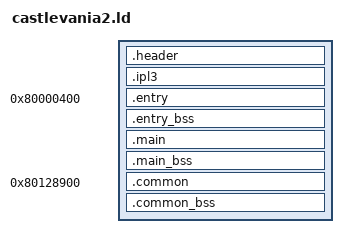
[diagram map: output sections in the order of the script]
SECTIONS
{
    __romPos = 0;
    header_ROM_START = __romPos;
    header_VRAM = ADDR(.header);
    .header : AT(header_ROM_START) SUBALIGN(16)
    {
        FILL(0x00000000);
        header_DATA_START = .;
        build/asm/header.o(.data);
        header_DATA_END = .;
        header_DATA_SIZE = ABSOLUTE(header_DATA_END - header_DATA_START);
    }
    __romPos += SIZEOF(.header);
    header_ROM_END = __romPos;
    header_VRAM_END = .;

    ipl3_ROM_START = __romPos;
    ipl3_VRAM = ADDR(.ipl3);
    .ipl3 : AT(ipl3_ROM_START) SUBALIGN(16)
    {
        FILL(0x00000000);
        ipl3_DATA_START = .;
        build/assets/ipl3.o(.data);
        ipl3_DATA_END = .;
        ipl3_DATA_SIZE = ABSOLUTE(ipl3_DATA_END - ipl3_DATA_START);
    }
    __romPos += SIZEOF(.ipl3);
    ipl3_ROM_END = __romPos;
    ipl3_VRAM_END = .;

    entry_ROM_START = __romPos;
    entry_VRAM = ADDR(.entry);
    .entry 0x80000400 : AT(entry_ROM_START) SUBALIGN(16)
    {
        FILL(0x00000000);
        entry_TEXT_START = .;
        build/asm/1000.o(.text);
        . = ALIGN(., 16);
        entry_TEXT_END = .;
        entry_TEXT_SIZE = ABSOLUTE(entry_TEXT_END - entry_TEXT_START);
        entry_DATA_START = .;
        build/asm/1000.o(.data);
        . = ALIGN(., 16);
        entry_DATA_END = .;
        entry_DATA_SIZE = ABSOLUTE(entry_DATA_END - entry_DATA_START);
        entry_RODATA_START = .;
        build/asm/1000.o(.rodata);
        . = ALIGN(., 16);
        entry_RODATA_END = .;
        entry_RODATA_SIZE = ABSOLUTE(entry_RODATA_END - entry_RODATA_START);
    }
    entry_bss_VRAM = ADDR(.entry_bss);
    .entry_bss (NOLOAD) : SUBALIGN(16)
    {
        FILL(0x00000000);
        entry_BSS_START = .;
        build/asm/1000.o(.bss);
        . = ALIGN(., 16);
        entry_BSS_END = .;
        entry_BSS_SIZE = ABSOLUTE(entry_BSS_END - entry_BSS_START);
    }
    __romPos += SIZEOF(.entry);
    __romPos = ALIGN(__romPos, 16);
    . = ALIGN(., 16);
    entry_ROM_END = __romPos;
    entry_VRAM_END = .;

    main_ROM_START = __romPos;
    main_VRAM = ADDR(.main);
    .main entry_VRAM_END : AT(main_ROM_START) SUBALIGN(16)
    {
        FILL(0x00000000);
        main_TEXT_START = .;
        build/asm/gamestate.o(.text);
        build/asm/memory.o(.text);
        build/asm/object.o(.text);
        build/asm/3550.o(.text);
        build/asm/4BC0.o(.text);
        build/asm/4D80.o(.text);
        build/asm/figure.o(.text);
        build/asm/D270.o(.text);
        build/asm/DD70.o(.text);
        build/asm/fade.o(.text);
        build/asm/object_flow.o(.text);
        build/asm/F960.o(.text);
        build/asm/10100.o(.text);
        build/asm/dma_manager.o(.text);
        build/asm/113D0.o(.text);
        build/asm/vec3f.o(.text);
        build/asm/12700.o(.text);
        build/asm/12900.o(.text);
        build/asm/main.o(.text);
        build/asm/15C80.o(.text);
        build/asm/16510.o(.text);
        build/asm/16640.o(.text);
        build/asm/scheduler.o(.text);
        build/asm/17040.o(.text);
        build/asm/172F0.o(.text);
        build/asm/controller.o(.text);
        build/asm/17A00.o(.text);
        build/asm/dma.o(.text);
        build/asm/18430.o(.text);
        build/asm/18E40.o(.text);
        build/asm/18FC0.o(.text);
        build/asm/19340.o(.text);
        build/asm/19570.o(.text);
        build/asm/19620.o(.text);
        build/asm/19630.o(.text);
        build/asm/19E20.o(.text);
        build/asm/19F40.o(.text);
        build/asm/crash_screen_init.o(.text);
        build/asm/debug.o(.text);
        build/asm/1AE50.o(.text);
        build/asm/controller_pak.o(.text);
        build/asm/save.o(.text);
        build/asm/1C830.o(.text);
        build/asm/22350.o(.text);
        build/asm/25F80.o(.text);
        build/asm/2BC60.o(.text);
        build/asm/2D5D0.o(.text);
        build/asm/2FA90.o(.text);
        build/asm/333F0.o(.text);
        build/asm/39330.o(.text);
        build/asm/enemy_list.o(.text);
        build/asm/3F870.o(.text);
        build/asm/407B0.o(.text);
        build/asm/atari.o(.text);
        build/asm/451C0.o(.text);
        build/asm/458C0.o(.text);
        build/asm/45C80.o(.text);
        build/asm/46140.o(.text);
        build/asm/46520.o(.text);
        build/asm/47AA0.o(.text);
        build/asm/47FD0.o(.text);
        build/asm/483A0.o(.text);
        build/asm/48780.o(.text);
        build/asm/48B40.o(.text);
        build/asm/49100.o(.text);
        build/asm/49D80.o(.text);
        build/asm/4A310.o(.text);
        build/asm/4ADB0.o(.text);
        build/asm/4B630.o(.text);
        build/asm/4C0A0.o(.text);
        build/asm/4C7A0.o(.text);
        build/asm/4CDE0.o(.text);
        build/asm/4D470.o(.text);
        build/asm/effect/fire.o(.text);
        build/asm/4DEC0.o(.text);
        build/asm/4F3C0.o(.text);
        build/asm/4F5E0.o(.text);
        build/asm/51CB0.o(.text);
        build/asm/52710.o(.text);
        build/asm/52910.o(.text);
        build/asm/52D50.o(.text);
        build/asm/54E70.o(.text);
        build/asm/55050.o(.text);
        build/asm/552F0.o(.text);
        build/asm/554D0.o(.text);
        build/asm/556B0.o(.text);
        build/asm/55890.o(.text);
        build/asm/55C90.o(.text);
        build/asm/55E70.o(.text);
        build/asm/effect/fire_sparkles.o(.text);
        build/asm/566D0.o(.text);
        build/asm/56B60.o(.text);
        build/asm/57050.o(.text);
        build/asm/574C0.o(.text);
        build/asm/5B620.o(.text);
        build/asm/5B7E0.o(.text);
        build/asm/effect_manager.o(.text);
        build/asm/effect.o(.text);
        build/asm/610F0.o(.text);
        build/asm/63A60.o(.text);
        build/asm/6A4A0.o(.text);
        build/asm/6A990.o(.text);
        build/asm/6AE70.o(.text);
        build/asm/6C0B0.o(.text);
        build/asm/6CB40.o(.text);
        build/asm/70460.o(.text);
        build/asm/70C90.o(.text);
        build/asm/71180.o(.text);
        build/asm/72060.o(.text);
        build/asm/72700.o(.text);
        build/asm/72D90.o(.text);
        build/asm/72DA0.o(.text);
        build/asm/72DB0.o(.text);
        build/asm/73D80.o(.text);
        build/asm/750B0.o(.text);
        build/asm/75730.o(.text);
        build/asm/76AE0.o(.text);
        build/asm/audio/audioMgr.o(.text);
        build/asm/audio/audio.o(.text);
        build/asm/7CBB0.o(.text);
        build/asm/7E080.o(.text);
        build/asm/libultra/os/sendmesg.o(.text);
        build/asm/libultra/io/pfsfreeblocks.o(.text);
        build/asm/libultra/gu/perspective.o(.text);
        build/asm/libultra/os/recvmesg.o(.text);
        build/asm/libultra/os/setintmask.o(.text);
        build/asm/libultra/al/sl.o(.text);
        build/asm/libultra/gu/align.o(.text);
        build/asm/libultra/gu/sinf.o(.text);
        build/asm/libultra/gu/sins.o(.text);
        build/asm/libultra/al/synsetvol.o(.text);
        build/asm/libultra/io/sptask.o(.text);
        build/asm/libultra/os/os_tlb.o(.text);
        build/asm/libultra/os/exceptasm.o(.text);
        build/asm/libultra/os/thread.o(.text);
        build/asm/libultra/os/destroythread.o(.text);
        build/asm/libultra/io/piread.o(.text);
        build/asm/libultra/io/piacs.o(.text);
        build/asm/libultra/io/controller.o(.text);
        build/asm/libultra/io/siacs.o(.text);
        build/asm/libultra/os/createthread.o(.text);
        build/asm/libultra/io/contreaddata.o(.text);
        build/asm/libultra/gu/rotate.o(.text);
        build/asm/libultra/al/synallocvoice.o(.text);
        build/asm/libultra/os/virtualtophysical.o(.text);
        build/asm/libultra/os/writebackdcache.o(.text);
        build/asm/libultra/os/initialize.o(.text);
        build/asm/libultra/libc/ll.o(.text);
        build/asm/libultra/libc/bzero.o(.text);
        build/asm/libultra/os/setsr.o(.text);
        build/asm/libultra/os/getsr.o(.text);
        build/asm/libultra/audio/synsetfxparam.o(.text);
        build/asm/libultra/io/vigetnextframebuf.o(.text);
        build/asm/libultra/audio/synstartvoice.o(.text);
        build/asm/libultra/io/sprawdma.o(.text);
        build/asm/libultra/io/sirawdma.o(.text);
        build/asm/libultra/io/viblack.o(.text);
        build/asm/libultra/io/pirawread.o(.text);
        build/asm/libultra/io/sirawread.o(.text);
        build/asm/libultra/io/sptaskyield.o(.text);
        build/asm/libultra/io/pfsreadwritefile.o(.text);
        build/asm/libultra/io/pfsgetstatus.o(.text);
        build/asm/libultra/gu/mtxutil.o(.text);
        build/asm/libultra/io/visetmode.o(.text);
        build/asm/libultra/io/motor.o(.text);
        build/asm/libultra/io/pfsallocatefile.o(.text);
        build/asm/libultra/io/pfsisplug.o(.text);
        build/asm/libultra/audio/synsetpitch.o(.text);
        build/asm/libultra/os/probetlb.o(.text);
        build/asm/libultra/io/pimgr.o(.text);
        build/asm/libultra/io/devmgr.o(.text);
        build/asm/libultra/io/pirawdma.o(.text);
        build/asm/libultra/audio/synsetpan.o(.text);
        build/asm/libultra/os/getcount.o(.text);
        build/asm/libultra/io/contpfs.o(.text);
        build/asm/libultra/io/pidma.o(.text);
        build/asm/libultra/io/pfssearchfile.o(.text);
        build/asm/libultra/audio/synthesizer.o(.text);
        build/asm/libultra/audio/drvrnew.o(.text);
        build/asm/libultra/audio/mainbus.o(.text);
        build/asm/libultra/audio/reverb.o(.text);
        build/asm/libultra/audio/auxbus.o(.text);
        build/asm/libultra/audio/env.o(.text);
        build/asm/libultra/audio/resample.o(.text);
        build/asm/libultra/audio/load.o(.text);
        build/asm/libultra/os/seteventmesg.o(.text);
        build/asm/libultra/gu/sqrtf.o(.text);
        build/asm/libultra/os/afterprenmi.o(.text);
        build/asm/libultra/io/contquery.o(.text);
        build/asm/libultra/gu/random.o(.text);
        build/asm/libultra/os/unmaptlb.o(.text);
        build/asm/libultra/libc/xprintf.o(.text);
        build/asm/libultra/audio/filter.o(.text);
        build/asm/libultra/gu/ortho.o(.text);
        build/asm/libultra/os/unmaptlball.o(.text);
        build/asm/libultra/io/epidma.o(.text);
        build/asm/libultra/audio/heapinit.o(.text);
        build/asm/libultra/libc/string.o(.text);
        build/asm/libultra/os/invalicache.o(.text);
        build/asm/libultra/os/createmesgqueue.o(.text);
        build/asm/libultra/os/invaldcache.o(.text);
        build/asm/libultra/audio/synsetfxmix.o(.text);
        build/asm/libultra/audio/save.o(.text);
        build/asm/libultra/io/pfsrepairid.o(.text);
        build/asm/libultra/audio/syngetfxref.o(.text);
        build/asm/libultra/io/sp.o(.text);
        build/asm/libultra/io/si.o(.text);
        build/asm/libultra/gu/translate.o(.text);
        build/asm/libultra/os/jammesg.o(.text);
        build/asm/libultra/os/setthreadpri.o(.text);
        build/asm/libultra/os/getthreadpri.o(.text);
        build/asm/libultra/io/epirawread.o(.text);
        build/asm/libultra/io/viswapbuf.o(.text);
        build/asm/libultra/gu/lookat.o(.text);
        build/asm/libultra/gu/position.o(.text);
        build/asm/libultra/io/epirawdma.o(.text);
        build/asm/libultra/io/sptaskyielded.o(.text);
        build/asm/libultra/libc/bcmp.o(.text);
        build/asm/libultra/os/gettime.o(.text);
        build/asm/libultra/os/timerintr.o(.text);
        build/asm/libultra/os/setglobalintmask.o(.text);
        build/asm/libultra/io/aisetfreq.o(.text);
        build/asm/libultra/gu/normalize.o(.text);
        build/asm/libultra/os/setcompare.o(.text);
        build/asm/libultra/libc/bcopy.o(.text);
        build/asm/libultra/audio/copy.o(.text);
        build/asm/libultra/os/resetglobalintmask.o(.text);
        build/asm/libultra/io/pfsdeletefile.o(.text);
        build/asm/libultra/os/interrupt.o(.text);
        build/asm/libultra/io/vi.o(.text);
        build/asm/libultra/io/viswapcontext.o(.text);
        build/asm/libultra/io/pigetcmdq.o(.text);
        build/asm/libultra/gu/cosf.o(.text);
        build/asm/libultra/gu/coss.o(.text);
        build/asm/libultra/io/visetspecial.o(.text);
        build/asm/libultra/io/visetevent.o(.text);
        build/asm/libultra/audio/synaddplayer.o(.text);
        build/asm/libultra/io/pfsnumfiles.o(.text);
        build/asm/libultra/io/cartrominit.o(.text);
        build/asm/libultra/io/pfsselectbank.o(.text);
        build/asm/libultra/os/setfpccsr.o(.text);
        build/asm/libultra/io/pfsfilestate.o(.text);
        build/asm/libultra/io/pfsinitpak.o(.text);
        build/asm/libultra/io/pfschecker.o(.text);
        build/asm/libultra/io/aigetlen.o(.text);
        build/asm/libultra/io/piwrite.o(.text);
        build/asm/libultra/os/maptlbrdb.o(.text);
        build/asm/libultra/os/yieldthread.o(.text);
        build/asm/libultra/audio/synstartvoiceparam.o(.text);
        build/asm/libultra/os/getcause.o(.text);
        build/asm/libultra/io/contramwrite.o(.text);
        build/asm/libultra/io/contramread.o(.text);
        build/asm/libultra/io/crc.o(.text);
        build/asm/libultra/io/epirawwrite.o(.text);
        build/asm/libultra/os/settimer.o(.text);
        build/asm/libultra/libc/xldtob.o(.text);
        build/asm/libultra/libc/ldiv.o(.text);
        build/asm/libultra/libc/xlitob.o(.text);
        build/asm/libultra/io/sirawwrite.o(.text);
        build/asm/libultra/io/pirawwrite.o(.text);
        build/asm/libultra/io/spsetstat.o(.text);
        build/asm/libultra/io/spgetstat.o(.text);
        build/asm/libultra/io/vimgr.o(.text);
        build/asm/libultra/io/vigetcurrcontext.o(.text);
        build/asm/libultra/os/writebackdcacheall.o(.text);
        build/asm/libultra/audio/heapalloc.o(.text);
        build/asm/libultra/os/getcurrfaultthread.o(.text);
        build/asm/libultra/gu/rotaterpy.o(.text);
        build/asm/libultra/libc/llcvt.o(.text);
        build/asm/libultra/os/startthread.o(.text);
        build/asm/libultra/io/visetyscale.o(.text);
        build/asm/libultra/audio/synallocfx.o(.text);
        build/asm/libultra/audio/synstopvoice.o(.text);
        build/asm/libultra/audio/syndelete.o(.text);
        build/asm/libultra/io/aisetnextbuf.o(.text);
        build/asm/libultra/io/ai.o(.text);
        build/asm/libultra/io/vigetcurrframebuf.o(.text);
        build/asm/libultra/io/spsetpc.o(.text);
        . = ALIGN(., 16);
        main_TEXT_END = .;
        main_TEXT_SIZE = ABSOLUTE(main_TEXT_END - main_TEXT_START);
        main_DATA_START = .;
        build/asm/data/908D0.data.o(.data);
        build/asm/data/90920.data.o(.data);
        build/asm/data/gamestate.data.o(.data);
        build/asm/memory.o(.data);
        build/asm/data/object.data.o(.data);
        build/asm/3550.o(.data);
        build/asm/4BC0.o(.data);
        build/asm/data/4D80.data.o(.data);
        build/asm/data/93B50.data.o(.data);
        build/asm/data/figure.data.o(.data);
        build/asm/data/D270.data.o(.data);
        build/asm/data/fade.data.o(.data);
        build/asm/data/F960.data.o(.data);
        build/asm/data/10100.data.o(.data);
        build/asm/dma_manager.o(.data);
        build/asm/data/DMAMgr.data.o(.data);
        build/asm/data/113D0.data.o(.data);
        build/asm/vec3f.o(.data);
        build/asm/12700.o(.data);
        build/asm/data/94940.data.o(.data);
        build/asm/data/19630.data.o(.data);
        build/asm/19E20.o(.data);
        build/asm/19F40.o(.data);
        build/asm/data/crash_screen_init.data.o(.data);
        build/asm/data/func_80096760.data.o(.data);
        build/asm/data/func_800968B0.data.o(.data);
        build/asm/data/func_80096A50.data.o(.data);
        build/asm/data/debug.data.o(.data);
        build/asm/data/save.data.o(.data);
        build/asm/data/97710.data.o(.data);
        build/asm/data/enemy_list.data.o(.data);
        build/asm/3F870.o(.data);
        build/asm/407B0.o(.data);
        build/asm/data/atari.data.o(.data);
        build/asm/451C0.o(.data);
        build/asm/458C0.o(.data);
        build/asm/45C80.o(.data);
        build/asm/46140.o(.data);
        build/asm/46520.o(.data);
        build/asm/47AA0.o(.data);
        build/asm/47FD0.o(.data);
        build/asm/483A0.o(.data);
        build/asm/48780.o(.data);
        build/asm/48B40.o(.data);
        build/asm/49100.o(.data);
        build/asm/49D80.o(.data);
        build/asm/4A310.o(.data);
        build/asm/4ADB0.o(.data);
        build/asm/4B630.o(.data);
        build/asm/4C0A0.o(.data);
        build/asm/4C7A0.o(.data);
        build/asm/4CDE0.o(.data);
        build/asm/4D470.o(.data);
        build/asm/data/effect/fire.data.o(.data);
        build/asm/4DEC0.o(.data);
        build/asm/4F3C0.o(.data);
        build/asm/4F5E0.o(.data);
        build/asm/51CB0.o(.data);
        build/asm/52710.o(.data);
        build/asm/52910.o(.data);
        build/asm/52D50.o(.data);
        build/asm/54E70.o(.data);
        build/asm/55050.o(.data);
        build/asm/552F0.o(.data);
        build/asm/554D0.o(.data);
        build/asm/556B0.o(.data);
        build/asm/55890.o(.data);
        build/asm/55C90.o(.data);
        build/asm/55E70.o(.data);
        build/asm/data/9B680.data.o(.data);
        build/asm/data/effect/fire_sparkles.data.o(.data);
        build/asm/566D0.o(.data);
        build/asm/data/9B8B0.data.o(.data);
        build/asm/data/56B60.data.o(.data);
        build/asm/data/57050.data.o(.data);
        build/asm/data/574C0.data.o(.data);
        build/asm/data/5B620.data.o(.data);
        build/asm/data/5B7E0.data.o(.data);
        build/asm/data/effect_manager.data.o(.data);
        build/asm/effect.o(.data);
        build/asm/610F0.o(.data);
        build/asm/63A60.o(.data);
        build/asm/6A4A0.o(.data);
        build/asm/6A990.o(.data);
        build/asm/6AE70.o(.data);
        build/asm/6C0B0.o(.data);
        build/asm/6CB40.o(.data);
        build/asm/70460.o(.data);
        build/asm/70C90.o(.data);
        build/asm/71180.o(.data);
        build/asm/72060.o(.data);
        build/asm/72700.o(.data);
        build/asm/72D90.o(.data);
        build/asm/72DA0.o(.data);
        build/asm/72DB0.o(.data);
        build/asm/73D80.o(.data);
        build/asm/750B0.o(.data);
        build/asm/75730.o(.data);
        build/asm/76AE0.o(.data);
        build/asm/data/9B970.data.o(.data);
        build/asm/data/libultra/os/initialize.data.o(.data);
        build/asm/libultra/libc/ll.o(.data);
        build/asm/libultra/libc/bzero.o(.data);
        build/asm/libultra/os/setsr.o(.data);
        build/asm/libultra/os/getsr.o(.data);
        build/asm/libultra/audio/synsetfxparam.o(.data);
        build/asm/libultra/io/vigetnextframebuf.o(.data);
        build/asm/libultra/audio/synstartvoice.o(.data);
        build/asm/libultra/io/sprawdma.o(.data);
        build/asm/libultra/io/sirawdma.o(.data);
        build/asm/libultra/io/viblack.o(.data);
        build/asm/libultra/io/pirawread.o(.data);
        build/asm/libultra/io/sirawread.o(.data);
        build/asm/libultra/io/sptaskyield.o(.data);
        build/asm/libultra/io/pfsreadwritefile.o(.data);
        build/asm/libultra/io/pfsgetstatus.o(.data);
        build/asm/libultra/gu/mtxutil.o(.data);
        build/asm/libultra/io/visetmode.o(.data);
        build/asm/libultra/io/motor.o(.data);
        build/asm/libultra/io/pfsallocatefile.o(.data);
        build/asm/libultra/io/pfsisplug.o(.data);
        build/asm/libultra/audio/synsetpitch.o(.data);
        build/asm/libultra/os/probetlb.o(.data);
        build/asm/data/libultra/io/pimgr.data.o(.data);
        build/asm/data/libultra/io/contpfs.data.o(.data);
        build/asm/libultra/io/pidma.o(.data);
        build/asm/libultra/io/pfssearchfile.o(.data);
        build/asm/data/libultra/audio/drvrnew.data.o(.data);
        build/asm/data/libultra/audio/env.data.o(.data);
        build/asm/data/func_800A23B0.data.o(.data);
        build/asm/data/libultra/os/seteventmesg.data.o(.data);
        build/asm/libultra/gu/sqrtf.o(.data);
        build/asm/libultra/os/afterprenmi.o(.data);
        build/asm/libultra/io/contquery.o(.data);
        build/asm/data/libultra/gu/random.data.o(.data);
        build/asm/libultra/os/unmaptlb.o(.data);
        build/asm/data/libultra/libc/xprintf.data.o(.data);
        build/asm/data/libultra/os/timerintr.data.o(.data);
        build/asm/libultra/os/setglobalintmask.o(.data);
        build/asm/libultra/io/aisetfreq.o(.data);
        build/asm/libultra/gu/normalize.o(.data);
        build/asm/libultra/os/setcompare.o(.data);
        build/asm/libultra/libc/bcopy.o(.data);
        build/asm/libultra/audio/copy.o(.data);
        build/asm/libultra/os/resetglobalintmask.o(.data);
        build/asm/libultra/io/pfsdeletefile.o(.data);
        build/asm/libultra/os/interrupt.o(.data);
        build/asm/data/libultra/io/vi.data.o(.data);
        build/asm/libultra/io/viswapcontext.o(.data);
        build/asm/libultra/io/pigetcmdq.o(.data);
        build/asm/data/A31B0.data.o(.data);
        build/asm/data/libultra/io/cartrominit.data.o(.data);
        build/asm/libultra/io/pfsselectbank.o(.data);
        build/asm/libultra/os/setfpccsr.o(.data);
        build/asm/libultra/io/pfsfilestate.o(.data);
        build/asm/libultra/io/pfsinitpak.o(.data);
        build/asm/libultra/io/pfschecker.o(.data);
        build/asm/libultra/io/aigetlen.o(.data);
        build/asm/libultra/io/piwrite.o(.data);
        build/asm/libultra/os/maptlbrdb.o(.data);
        build/asm/libultra/os/yieldthread.o(.data);
        build/asm/libultra/audio/synstartvoiceparam.o(.data);
        build/asm/libultra/os/getcause.o(.data);
        build/asm/libultra/io/contramwrite.o(.data);
        build/asm/data/libultra/io/contramread.data.o(.data);
        build/asm/libultra/io/crc.o(.data);
        build/asm/libultra/io/epirawwrite.o(.data);
        build/asm/libultra/os/settimer.o(.data);
        build/asm/data/libultra/libc/xlitob.data.o(.data);
        build/asm/libultra/io/sirawwrite.o(.data);
        build/asm/libultra/io/pirawwrite.o(.data);
        build/asm/libultra/io/spsetstat.o(.data);
        build/asm/libultra/io/spgetstat.o(.data);
        build/asm/data/libultra/io/vimgr.data.o(.data);
        build/asm/libultra/io/vigetcurrcontext.o(.data);
        build/asm/libultra/os/writebackdcacheall.o(.data);
        build/asm/libultra/audio/heapalloc.o(.data);
        build/asm/libultra/os/getcurrfaultthread.o(.data);
        build/asm/data/libultra/io/aisetnextbuf.data.o(.data);
        build/asm/libultra/io/ai.o(.data);
        build/asm/libultra/io/vigetcurrframebuf.o(.data);
        build/asm/libultra/io/spsetpc.o(.data);
        build/asm/data/4D80.data.o(.data);
        build/asm/data/figure.data.o(.data);
        build/asm/data/D270.data.o(.data);
        build/asm/data/DD70.data.o(.data);
        build/asm/data/fade.data.o(.data);
        build/asm/object_flow.o(.data);
        build/asm/data/A33C0.data.o(.data);
        build/asm/data/A3410.data.o(.data);
        build/asm/data/12900.data.o(.data);
        build/asm/main.o(.data);
        build/asm/15C80.o(.data);
        build/asm/16510.o(.data);
        build/asm/16640.o(.data);
        build/asm/scheduler.o(.data);
        build/asm/data/17A00.data.o(.data);
        build/asm/dma.o(.data);
        build/asm/18430.o(.data);
        build/asm/18E40.o(.data);
        build/asm/18FC0.o(.data);
        build/asm/19340.o(.data);
        build/asm/19570.o(.data);
        build/asm/19620.o(.data);
        build/asm/data/crash_screen_init.data.o(.data);
        build/asm/data/debug.data.o(.data);
        build/asm/1AE50.o(.data);
        build/asm/controller_pak.o(.data);
        build/asm/data/save.data.o(.data);
        build/asm/1C830.o(.data);
        build/asm/22350.o(.data);
        build/asm/25F80.o(.data);
        build/asm/2BC60.o(.data);
        build/asm/2D5D0.o(.data);
        build/asm/2FA90.o(.data);
        build/asm/333F0.o(.data);
        build/asm/39330.o(.data);
        build/asm/data/A3D10.data.o(.data);
        build/asm/data/A41E0.data.o(.data);
        build/asm/data/A4310.data.o(.data);
        build/asm/data/A45A0.data.o(.data);
        build/asm/data/A4650.data.o(.data);
        build/asm/data/A4670.data.o(.data);
        build/asm/data/A49E0.data.o(.data);
        build/asm/data/A6A20.data.o(.data);
        build/asm/data/A6C40.data.o(.data);
        build/asm/data/A6CD0.data.o(.data);
        build/asm/data/A6E70.data.o(.data);
        build/asm/data/A6E90.data.o(.data);
        build/asm/data/A6EB0.data.o(.data);
        build/asm/data/A7000.data.o(.data);
        build/asm/data/A70E0.data.o(.data);
        build/asm/data/A7100.data.o(.data);
        build/asm/data/A7280.data.o(.data);
        build/asm/data/A72B0.data.o(.data);
        build/asm/data/A7360.data.o(.data);
        build/asm/data/A73A0.data.o(.data);
        build/asm/data/A73D0.data.o(.data);
        build/asm/data/A7400.data.o(.data);
        build/asm/data/A7420.data.o(.data);
        build/asm/data/A7480.data.o(.data);
        build/asm/data/A74C0.data.o(.data);
        build/asm/data/A7500.data.o(.data);
        build/asm/data/A75F0.data.o(.data);
        build/asm/data/A7790.data.o(.data);
        build/asm/data/A78C0.data.o(.data);
        build/asm/data/libultra/gu/perspective.data.o(.data);
        build/asm/libultra/os/recvmesg.o(.data);
        build/asm/libultra/os/setintmask.o(.data);
        build/asm/libultra/al/sl.o(.data);
        build/asm/data/A78F0.data.o(.data);
        build/asm/data/libultra/gu/align.data.o(.data);
        build/asm/data/libultra/gu/sinf.data.o(.data);
        build/asm/libultra/gu/sins.o(.data);
        build/asm/libultra/al/synsetvol.o(.data);
        build/asm/libultra/io/sptask.o(.data);
        build/asm/libultra/os/os_tlb.o(.data);
        build/asm/data/libultra/os/exceptasm.data.o(.data);
        build/asm/libultra/os/thread.o(.data);
        build/asm/libultra/os/destroythread.o(.data);
        build/asm/libultra/io/piread.o(.data);
        build/asm/libultra/io/piacs.o(.data);
        build/asm/libultra/io/controller.o(.data);
        build/asm/libultra/io/siacs.o(.data);
        build/asm/libultra/os/createthread.o(.data);
        build/asm/libultra/io/contreaddata.o(.data);
        build/asm/data/libultra/gu/rotate.data.o(.data);
        build/asm/libultra/al/synallocvoice.o(.data);
        build/asm/libultra/os/virtualtophysical.o(.data);
        build/asm/libultra/os/writebackdcache.o(.data);
        build/asm/data/libultra/io/devmgr.data.o(.data);
        build/asm/libultra/io/pirawdma.o(.data);
        build/asm/libultra/audio/synsetpan.o(.data);
        build/asm/libultra/os/getcount.o(.data);
        build/asm/data/libultra/audio/synthesizer.data.o(.data);
        build/asm/data/libultra/audio/drvrnew.data.o(.data);
        build/asm/libultra/audio/mainbus.o(.data);
        build/asm/data/libultra/audio/reverb.data.o(.data);
        build/asm/libultra/audio/auxbus.o(.data);
        build/asm/data/libultra/audio/env.data.o(.data);
        build/asm/data/libultra/audio/resample.data.o(.data);
        build/asm/libultra/audio/load.o(.data);
        build/asm/data/libultra/libc/xprintf.data.o(.data);
        build/asm/libultra/audio/filter.o(.data);
        build/asm/libultra/gu/ortho.o(.data);
        build/asm/libultra/os/unmaptlball.o(.data);
        build/asm/libultra/io/epidma.o(.data);
        build/asm/libultra/audio/heapinit.o(.data);
        build/asm/libultra/libc/string.o(.data);
        build/asm/libultra/os/invalicache.o(.data);
        build/asm/libultra/os/createmesgqueue.o(.data);
        build/asm/libultra/os/invaldcache.o(.data);
        build/asm/libultra/audio/synsetfxmix.o(.data);
        build/asm/libultra/audio/save.o(.data);
        build/asm/libultra/io/pfsrepairid.o(.data);
        build/asm/libultra/audio/syngetfxref.o(.data);
        build/asm/libultra/io/sp.o(.data);
        build/asm/libultra/io/si.o(.data);
        build/asm/libultra/gu/translate.o(.data);
        build/asm/libultra/os/jammesg.o(.data);
        build/asm/libultra/os/setthreadpri.o(.data);
        build/asm/libultra/os/getthreadpri.o(.data);
        build/asm/libultra/io/epirawread.o(.data);
        build/asm/libultra/io/viswapbuf.o(.data);
        build/asm/libultra/gu/lookat.o(.data);
        build/asm/data/libultra/gu/position.data.o(.data);
        build/asm/libultra/io/epirawdma.o(.data);
        build/asm/libultra/io/sptaskyielded.o(.data);
        build/asm/libultra/libc/bcmp.o(.data);
        build/asm/libultra/os/gettime.o(.data);
        build/asm/data/libultra/gu/cosf.data.o(.data);
        build/asm/libultra/gu/coss.o(.data);
        build/asm/libultra/io/visetspecial.o(.data);
        build/asm/libultra/io/visetevent.o(.data);
        build/asm/libultra/audio/synaddplayer.o(.data);
        build/asm/libultra/io/pfsnumfiles.o(.data);
        build/asm/data/libultra/gu/libm_vals.data.o(.data);
        build/asm/data/libultra/libc/xldtob.data.o(.data);
        build/asm/libultra/libc/ldiv.o(.data);
        build/asm/data/libultra/gu/rotaterpy.data.o(.data);
        build/asm/data/libultra/libc/llcvt.data.o(.data);
        build/asm/libultra/os/startthread.o(.data);
        build/asm/libultra/io/visetyscale.o(.data);
        build/asm/libultra/audio/synallocfx.o(.data);
        build/asm/libultra/audio/synstopvoice.o(.data);
        build/asm/libultra/audio/syndelete.o(.data);
        build/asm/data/17040.data.o(.data);
        build/asm/172F0.o(.data);
        build/asm/controller.o(.data);
        build/asm/data/audio/audioMgr.data.o(.data);
        build/asm/audio/audio.o(.data);
        build/asm/7CBB0.o(.data);
        build/asm/7E080.o(.data);
        build/asm/libultra/os/sendmesg.o(.data);
        build/asm/libultra/io/pfsfreeblocks.o(.data);
        . = ALIGN(., 16);
        main_DATA_END = .;
        main_DATA_SIZE = ABSOLUTE(main_DATA_END - main_DATA_START);
        main_RODATA_START = .;
        build/asm/gamestate.o(.rodata);
        build/asm/memory.o(.rodata);
        build/asm/object.o(.rodata);
        build/asm/3550.o(.rodata);
        build/asm/4BC0.o(.rodata);
        build/asm/4D80.o(.rodata);
        build/asm/figure.o(.rodata);
        build/asm/D270.o(.rodata);
        build/asm/DD70.o(.rodata);
        build/asm/fade.o(.rodata);
        build/asm/object_flow.o(.rodata);
        build/asm/F960.o(.rodata);
        build/asm/10100.o(.rodata);
        build/asm/dma_manager.o(.rodata);
        build/asm/113D0.o(.rodata);
        build/asm/vec3f.o(.rodata);
        build/asm/12700.o(.rodata);
        build/asm/12900.o(.rodata);
        build/asm/main.o(.rodata);
        build/asm/15C80.o(.rodata);
        build/asm/16510.o(.rodata);
        build/asm/16640.o(.rodata);
        build/asm/scheduler.o(.rodata);
        build/asm/17040.o(.rodata);
        build/asm/172F0.o(.rodata);
        build/asm/controller.o(.rodata);
        build/asm/17A00.o(.rodata);
        build/asm/dma.o(.rodata);
        build/asm/18430.o(.rodata);
        build/asm/18E40.o(.rodata);
        build/asm/18FC0.o(.rodata);
        build/asm/19340.o(.rodata);
        build/asm/19570.o(.rodata);
        build/asm/19620.o(.rodata);
        build/asm/19630.o(.rodata);
        build/asm/19E20.o(.rodata);
        build/asm/19F40.o(.rodata);
        build/asm/crash_screen_init.o(.rodata);
        build/asm/debug.o(.rodata);
        build/asm/1AE50.o(.rodata);
        build/asm/controller_pak.o(.rodata);
        build/asm/save.o(.rodata);
        build/asm/1C830.o(.rodata);
        build/asm/22350.o(.rodata);
        build/asm/25F80.o(.rodata);
        build/asm/2BC60.o(.rodata);
        build/asm/2D5D0.o(.rodata);
        build/asm/2FA90.o(.rodata);
        build/asm/333F0.o(.rodata);
        build/asm/39330.o(.rodata);
        build/asm/enemy_list.o(.rodata);
        build/asm/3F870.o(.rodata);
        build/asm/407B0.o(.rodata);
        build/asm/atari.o(.rodata);
        build/asm/451C0.o(.rodata);
        build/asm/458C0.o(.rodata);
        build/asm/45C80.o(.rodata);
        build/asm/46140.o(.rodata);
        build/asm/46520.o(.rodata);
        build/asm/47AA0.o(.rodata);
        build/asm/47FD0.o(.rodata);
        build/asm/483A0.o(.rodata);
        build/asm/48780.o(.rodata);
        build/asm/48B40.o(.rodata);
        build/asm/49100.o(.rodata);
        build/asm/49D80.o(.rodata);
        build/asm/4A310.o(.rodata);
        build/asm/4ADB0.o(.rodata);
        build/asm/4B630.o(.rodata);
        build/asm/4C0A0.o(.rodata);
        build/asm/4C7A0.o(.rodata);
        build/asm/4CDE0.o(.rodata);
        build/asm/4D470.o(.rodata);
        build/asm/effect/fire.o(.rodata);
        build/asm/4DEC0.o(.rodata);
        build/asm/4F3C0.o(.rodata);
        build/asm/4F5E0.o(.rodata);
        build/asm/51CB0.o(.rodata);
        build/asm/52710.o(.rodata);
        build/asm/52910.o(.rodata);
        build/asm/52D50.o(.rodata);
        build/asm/54E70.o(.rodata);
        build/asm/55050.o(.rodata);
        build/asm/552F0.o(.rodata);
        build/asm/554D0.o(.rodata);
        build/asm/556B0.o(.rodata);
        build/asm/55890.o(.rodata);
        build/asm/55C90.o(.rodata);
        build/asm/55E70.o(.rodata);
        build/asm/effect/fire_sparkles.o(.rodata);
        build/asm/566D0.o(.rodata);
        build/asm/56B60.o(.rodata);
        build/asm/57050.o(.rodata);
        build/asm/574C0.o(.rodata);
        build/asm/5B620.o(.rodata);
        build/asm/5B7E0.o(.rodata);
        build/asm/effect_manager.o(.rodata);
        build/asm/effect.o(.rodata);
        build/asm/610F0.o(.rodata);
        build/asm/63A60.o(.rodata);
        build/asm/6A4A0.o(.rodata);
        build/asm/6A990.o(.rodata);
        build/asm/6AE70.o(.rodata);
        build/asm/6C0B0.o(.rodata);
        build/asm/6CB40.o(.rodata);
        build/asm/70460.o(.rodata);
        build/asm/70C90.o(.rodata);
        build/asm/71180.o(.rodata);
        build/asm/72060.o(.rodata);
        build/asm/72700.o(.rodata);
        build/asm/72D90.o(.rodata);
        build/asm/72DA0.o(.rodata);
        build/asm/72DB0.o(.rodata);
        build/asm/73D80.o(.rodata);
        build/asm/750B0.o(.rodata);
        build/asm/75730.o(.rodata);
        build/asm/76AE0.o(.rodata);
        build/asm/audio/audioMgr.o(.rodata);
        build/asm/audio/audio.o(.rodata);
        build/asm/7CBB0.o(.rodata);
        build/asm/7E080.o(.rodata);
        build/asm/libultra/os/sendmesg.o(.rodata);
        build/asm/libultra/io/pfsfreeblocks.o(.rodata);
        build/asm/libultra/gu/perspective.o(.rodata);
        build/asm/libultra/os/recvmesg.o(.rodata);
        build/asm/libultra/os/setintmask.o(.rodata);
        build/asm/libultra/al/sl.o(.rodata);
        build/asm/libultra/gu/align.o(.rodata);
        build/asm/libultra/gu/sinf.o(.rodata);
        build/asm/libultra/gu/sins.o(.rodata);
        build/asm/libultra/al/synsetvol.o(.rodata);
        build/asm/libultra/io/sptask.o(.rodata);
        build/asm/libultra/os/os_tlb.o(.rodata);
        build/asm/libultra/os/exceptasm.o(.rodata);
        build/asm/libultra/os/thread.o(.rodata);
        build/asm/libultra/os/destroythread.o(.rodata);
        build/asm/libultra/io/piread.o(.rodata);
        build/asm/libultra/io/piacs.o(.rodata);
        build/asm/libultra/io/controller.o(.rodata);
        build/asm/libultra/io/siacs.o(.rodata);
        build/asm/libultra/os/createthread.o(.rodata);
        build/asm/libultra/io/contreaddata.o(.rodata);
        build/asm/libultra/gu/rotate.o(.rodata);
        build/asm/libultra/al/synallocvoice.o(.rodata);
        build/asm/libultra/os/virtualtophysical.o(.rodata);
        build/asm/libultra/os/writebackdcache.o(.rodata);
        build/asm/libultra/os/initialize.o(.rodata);
        build/asm/libultra/libc/ll.o(.rodata);
        build/asm/libultra/libc/bzero.o(.rodata);
        build/asm/libultra/os/setsr.o(.rodata);
        build/asm/libultra/os/getsr.o(.rodata);
        build/asm/libultra/audio/synsetfxparam.o(.rodata);
        build/asm/libultra/io/vigetnextframebuf.o(.rodata);
        build/asm/libultra/audio/synstartvoice.o(.rodata);
        build/asm/libultra/io/sprawdma.o(.rodata);
        build/asm/libultra/io/sirawdma.o(.rodata);
        build/asm/libultra/io/viblack.o(.rodata);
        build/asm/libultra/io/pirawread.o(.rodata);
        build/asm/libultra/io/sirawread.o(.rodata);
        build/asm/libultra/io/sptaskyield.o(.rodata);
        build/asm/libultra/io/pfsreadwritefile.o(.rodata);
        build/asm/libultra/io/pfsgetstatus.o(.rodata);
        build/asm/libultra/gu/mtxutil.o(.rodata);
        build/asm/libultra/io/visetmode.o(.rodata);
        build/asm/libultra/io/motor.o(.rodata);
        build/asm/libultra/io/pfsallocatefile.o(.rodata);
        build/asm/libultra/io/pfsisplug.o(.rodata);
        build/asm/libultra/audio/synsetpitch.o(.rodata);
        build/asm/libultra/os/probetlb.o(.rodata);
        build/asm/libultra/io/pimgr.o(.rodata);
        build/asm/libultra/io/devmgr.o(.rodata);
        build/asm/libultra/io/pirawdma.o(.rodata);
        build/asm/libultra/audio/synsetpan.o(.rodata);
        build/asm/libultra/os/getcount.o(.rodata);
        build/asm/libultra/io/contpfs.o(.rodata);
        build/asm/libultra/io/pidma.o(.rodata);
        build/asm/libultra/io/pfssearchfile.o(.rodata);
        build/asm/libultra/audio/synthesizer.o(.rodata);
        build/asm/libultra/audio/drvrnew.o(.rodata);
        build/asm/libultra/audio/mainbus.o(.rodata);
        build/asm/libultra/audio/reverb.o(.rodata);
        build/asm/libultra/audio/auxbus.o(.rodata);
        build/asm/libultra/audio/env.o(.rodata);
        build/asm/libultra/audio/resample.o(.rodata);
        build/asm/libultra/audio/load.o(.rodata);
        build/asm/libultra/os/seteventmesg.o(.rodata);
        build/asm/libultra/gu/sqrtf.o(.rodata);
        build/asm/libultra/os/afterprenmi.o(.rodata);
        build/asm/libultra/io/contquery.o(.rodata);
        build/asm/libultra/gu/random.o(.rodata);
        build/asm/libultra/os/unmaptlb.o(.rodata);
        build/asm/libultra/libc/xprintf.o(.rodata);
        build/asm/libultra/audio/filter.o(.rodata);
        build/asm/libultra/gu/ortho.o(.rodata);
        build/asm/libultra/os/unmaptlball.o(.rodata);
        build/asm/libultra/io/epidma.o(.rodata);
        build/asm/libultra/audio/heapinit.o(.rodata);
        build/asm/libultra/libc/string.o(.rodata);
        build/asm/libultra/os/invalicache.o(.rodata);
        build/asm/libultra/os/createmesgqueue.o(.rodata);
        build/asm/libultra/os/invaldcache.o(.rodata);
        build/asm/libultra/audio/synsetfxmix.o(.rodata);
        build/asm/libultra/audio/save.o(.rodata);
        build/asm/libultra/io/pfsrepairid.o(.rodata);
        build/asm/libultra/audio/syngetfxref.o(.rodata);
        build/asm/libultra/io/sp.o(.rodata);
        build/asm/libultra/io/si.o(.rodata);
        build/asm/libultra/gu/translate.o(.rodata);
        build/asm/libultra/os/jammesg.o(.rodata);
        build/asm/libultra/os/setthreadpri.o(.rodata);
        build/asm/libultra/os/getthreadpri.o(.rodata);
        build/asm/libultra/io/epirawread.o(.rodata);
        build/asm/libultra/io/viswapbuf.o(.rodata);
        build/asm/libultra/gu/lookat.o(.rodata);
        build/asm/libultra/gu/position.o(.rodata);
        build/asm/libultra/io/epirawdma.o(.rodata);
        build/asm/libultra/io/sptaskyielded.o(.rodata);
        build/asm/libultra/libc/bcmp.o(.rodata);
        build/asm/libultra/os/gettime.o(.rodata);
        build/asm/libultra/os/timerintr.o(.rodata);
        build/asm/libultra/os/setglobalintmask.o(.rodata);
        build/asm/libultra/io/aisetfreq.o(.rodata);
        build/asm/libultra/gu/normalize.o(.rodata);
        build/asm/libultra/os/setcompare.o(.rodata);
        build/asm/libultra/libc/bcopy.o(.rodata);
        build/asm/libultra/audio/copy.o(.rodata);
        build/asm/libultra/os/resetglobalintmask.o(.rodata);
        build/asm/libultra/io/pfsdeletefile.o(.rodata);
        build/asm/libultra/os/interrupt.o(.rodata);
        build/asm/libultra/io/vi.o(.rodata);
        build/asm/libultra/io/viswapcontext.o(.rodata);
        build/asm/libultra/io/pigetcmdq.o(.rodata);
        build/asm/libultra/gu/cosf.o(.rodata);
        build/asm/libultra/gu/coss.o(.rodata);
        build/asm/libultra/io/visetspecial.o(.rodata);
        build/asm/libultra/io/visetevent.o(.rodata);
        build/asm/libultra/audio/synaddplayer.o(.rodata);
        build/asm/libultra/io/pfsnumfiles.o(.rodata);
        build/asm/libultra/io/cartrominit.o(.rodata);
        build/asm/libultra/io/pfsselectbank.o(.rodata);
        build/asm/libultra/os/setfpccsr.o(.rodata);
        build/asm/libultra/io/pfsfilestate.o(.rodata);
        build/asm/libultra/io/pfsinitpak.o(.rodata);
        build/asm/libultra/io/pfschecker.o(.rodata);
        build/asm/libultra/io/aigetlen.o(.rodata);
        build/asm/libultra/io/piwrite.o(.rodata);
        build/asm/libultra/os/maptlbrdb.o(.rodata);
        build/asm/libultra/os/yieldthread.o(.rodata);
        build/asm/libultra/audio/synstartvoiceparam.o(.rodata);
        build/asm/libultra/os/getcause.o(.rodata);
        build/asm/libultra/io/contramwrite.o(.rodata);
        build/asm/libultra/io/contramread.o(.rodata);
        build/asm/libultra/io/crc.o(.rodata);
        build/asm/libultra/io/epirawwrite.o(.rodata);
        build/asm/libultra/os/settimer.o(.rodata);
        build/asm/libultra/libc/xldtob.o(.rodata);
        build/asm/libultra/libc/ldiv.o(.rodata);
        build/asm/libultra/libc/xlitob.o(.rodata);
        build/asm/libultra/io/sirawwrite.o(.rodata);
        build/asm/libultra/io/pirawwrite.o(.rodata);
        build/asm/libultra/io/spsetstat.o(.rodata);
        build/asm/libultra/io/spgetstat.o(.rodata);
        build/asm/libultra/io/vimgr.o(.rodata);
        build/asm/libultra/io/vigetcurrcontext.o(.rodata);
        build/asm/libultra/os/writebackdcacheall.o(.rodata);
        build/asm/libultra/audio/heapalloc.o(.rodata);
        build/asm/libultra/os/getcurrfaultthread.o(.rodata);
        build/asm/libultra/gu/rotaterpy.o(.rodata);
        build/asm/libultra/libc/llcvt.o(.rodata);
        build/asm/libultra/os/startthread.o(.rodata);
        build/asm/libultra/io/visetyscale.o(.rodata);
        build/asm/libultra/audio/synallocfx.o(.rodata);
        build/asm/libultra/audio/synstopvoice.o(.rodata);
        build/asm/libultra/audio/syndelete.o(.rodata);
        build/asm/libultra/io/aisetnextbuf.o(.rodata);
        build/asm/libultra/io/ai.o(.rodata);
        build/asm/libultra/io/vigetcurrframebuf.o(.rodata);
        build/asm/libultra/io/spsetpc.o(.rodata);
        . = ALIGN(., 16);
        main_RODATA_END = .;
        main_RODATA_SIZE = ABSOLUTE(main_RODATA_END - main_RODATA_START);
    }
    main_bss_VRAM = ADDR(.main_bss);
    .main_bss (NOLOAD) : SUBALIGN(16)
    {
        FILL(0x00000000);
        main_BSS_START = .;
        build/asm/gamestate.o(.bss);
        build/asm/memory.o(.bss);
        build/asm/object.o(.bss);
        build/asm/3550.o(.bss);
        build/asm/4BC0.o(.bss);
        build/asm/4D80.o(.bss);
        build/asm/figure.o(.bss);
        build/asm/D270.o(.bss);
        build/asm/DD70.o(.bss);
        build/asm/fade.o(.bss);
        build/asm/object_flow.o(.bss);
        build/asm/F960.o(.bss);
        build/asm/10100.o(.bss);
        build/asm/dma_manager.o(.bss);
        build/asm/113D0.o(.bss);
        build/asm/vec3f.o(.bss);
        build/asm/12700.o(.bss);
        build/asm/12900.o(.bss);
        build/asm/main.o(.bss);
        build/asm/15C80.o(.bss);
        build/asm/16510.o(.bss);
        build/asm/16640.o(.bss);
        build/asm/scheduler.o(.bss);
        build/asm/17040.o(.bss);
        build/asm/172F0.o(.bss);
        build/asm/controller.o(.bss);
        build/asm/17A00.o(.bss);
        build/asm/dma.o(.bss);
        build/asm/18430.o(.bss);
        build/asm/18E40.o(.bss);
        build/asm/18FC0.o(.bss);
        build/asm/19340.o(.bss);
        build/asm/19570.o(.bss);
        build/asm/19620.o(.bss);
        build/asm/19630.o(.bss);
        build/asm/19E20.o(.bss);
        build/asm/19F40.o(.bss);
        build/asm/crash_screen_init.o(.bss);
        build/asm/debug.o(.bss);
        build/asm/1AE50.o(.bss);
        build/asm/controller_pak.o(.bss);
        build/asm/save.o(.bss);
        build/asm/1C830.o(.bss);
        build/asm/22350.o(.bss);
        build/asm/25F80.o(.bss);
        build/asm/2BC60.o(.bss);
        build/asm/2D5D0.o(.bss);
        build/asm/2FA90.o(.bss);
        build/asm/333F0.o(.bss);
        build/asm/39330.o(.bss);
        build/asm/enemy_list.o(.bss);
        build/asm/3F870.o(.bss);
        build/asm/407B0.o(.bss);
        build/asm/atari.o(.bss);
        build/asm/451C0.o(.bss);
        build/asm/458C0.o(.bss);
        build/asm/45C80.o(.bss);
        build/asm/46140.o(.bss);
        build/asm/46520.o(.bss);
        build/asm/47AA0.o(.bss);
        build/asm/47FD0.o(.bss);
        build/asm/483A0.o(.bss);
        build/asm/48780.o(.bss);
        build/asm/48B40.o(.bss);
        build/asm/49100.o(.bss);
        build/asm/49D80.o(.bss);
        build/asm/4A310.o(.bss);
        build/asm/4ADB0.o(.bss);
        build/asm/4B630.o(.bss);
        build/asm/4C0A0.o(.bss);
        build/asm/4C7A0.o(.bss);
        build/asm/4CDE0.o(.bss);
        build/asm/4D470.o(.bss);
        build/asm/effect/fire.o(.bss);
        build/asm/4DEC0.o(.bss);
        build/asm/4F3C0.o(.bss);
        build/asm/4F5E0.o(.bss);
        build/asm/51CB0.o(.bss);
        build/asm/52710.o(.bss);
        build/asm/52910.o(.bss);
        build/asm/52D50.o(.bss);
        build/asm/54E70.o(.bss);
        build/asm/55050.o(.bss);
        build/asm/552F0.o(.bss);
        build/asm/554D0.o(.bss);
        build/asm/556B0.o(.bss);
        build/asm/55890.o(.bss);
        build/asm/55C90.o(.bss);
        build/asm/55E70.o(.bss);
        build/asm/effect/fire_sparkles.o(.bss);
        build/asm/566D0.o(.bss);
        build/asm/56B60.o(.bss);
        build/asm/57050.o(.bss);
        build/asm/574C0.o(.bss);
        build/asm/5B620.o(.bss);
        build/asm/5B7E0.o(.bss);
        build/asm/effect_manager.o(.bss);
        build/asm/effect.o(.bss);
        build/asm/610F0.o(.bss);
        build/asm/63A60.o(.bss);
        build/asm/6A4A0.o(.bss);
        build/asm/6A990.o(.bss);
        build/asm/6AE70.o(.bss);
        build/asm/6C0B0.o(.bss);
        build/asm/6CB40.o(.bss);
        build/asm/70460.o(.bss);
        build/asm/70C90.o(.bss);
        build/asm/71180.o(.bss);
        build/asm/72060.o(.bss);
        build/asm/72700.o(.bss);
        build/asm/72D90.o(.bss);
        build/asm/72DA0.o(.bss);
        build/asm/72DB0.o(.bss);
        build/asm/73D80.o(.bss);
        build/asm/750B0.o(.bss);
        build/asm/75730.o(.bss);
        build/asm/76AE0.o(.bss);
        build/asm/audio/audioMgr.o(.bss);
        build/asm/audio/audio.o(.bss);
        build/asm/7CBB0.o(.bss);
        build/asm/7E080.o(.bss);
        build/asm/libultra/os/sendmesg.o(.bss);
        build/asm/libultra/io/pfsfreeblocks.o(.bss);
        build/asm/libultra/gu/perspective.o(.bss);
        build/asm/libultra/os/recvmesg.o(.bss);
        build/asm/libultra/os/setintmask.o(.bss);
        build/asm/libultra/al/sl.o(.bss);
        build/asm/libultra/gu/align.o(.bss);
        build/asm/libultra/gu/sinf.o(.bss);
        build/asm/libultra/gu/sins.o(.bss);
        build/asm/libultra/al/synsetvol.o(.bss);
        build/asm/libultra/io/sptask.o(.bss);
        build/asm/libultra/os/os_tlb.o(.bss);
        build/asm/libultra/os/exceptasm.o(.bss);
        build/asm/libultra/os/thread.o(.bss);
        build/asm/libultra/os/destroythread.o(.bss);
        build/asm/libultra/io/piread.o(.bss);
        build/asm/libultra/io/piacs.o(.bss);
        build/asm/libultra/io/controller.o(.bss);
        build/asm/libultra/io/siacs.o(.bss);
        build/asm/libultra/os/createthread.o(.bss);
        build/asm/libultra/io/contreaddata.o(.bss);
        build/asm/libultra/gu/rotate.o(.bss);
        build/asm/libultra/al/synallocvoice.o(.bss);
        build/asm/libultra/os/virtualtophysical.o(.bss);
        build/asm/libultra/os/writebackdcache.o(.bss);
        build/asm/libultra/os/initialize.o(.bss);
        build/asm/libultra/libc/ll.o(.bss);
        build/asm/libultra/libc/bzero.o(.bss);
        build/asm/libultra/os/setsr.o(.bss);
        build/asm/libultra/os/getsr.o(.bss);
        build/asm/libultra/audio/synsetfxparam.o(.bss);
        build/asm/libultra/io/vigetnextframebuf.o(.bss);
        build/asm/libultra/audio/synstartvoice.o(.bss);
        build/asm/libultra/io/sprawdma.o(.bss);
        build/asm/libultra/io/sirawdma.o(.bss);
        build/asm/libultra/io/viblack.o(.bss);
        build/asm/libultra/io/pirawread.o(.bss);
        build/asm/libultra/io/sirawread.o(.bss);
        build/asm/libultra/io/sptaskyield.o(.bss);
        build/asm/libultra/io/pfsreadwritefile.o(.bss);
        build/asm/libultra/io/pfsgetstatus.o(.bss);
        build/asm/libultra/gu/mtxutil.o(.bss);
        build/asm/libultra/io/visetmode.o(.bss);
        build/asm/libultra/io/motor.o(.bss);
        build/asm/libultra/io/pfsallocatefile.o(.bss);
        build/asm/libultra/io/pfsisplug.o(.bss);
        build/asm/libultra/audio/synsetpitch.o(.bss);
        build/asm/libultra/os/probetlb.o(.bss);
        build/asm/libultra/io/pimgr.o(.bss);
        build/asm/libultra/io/devmgr.o(.bss);
        build/asm/libultra/io/pirawdma.o(.bss);
        build/asm/libultra/audio/synsetpan.o(.bss);
        build/asm/libultra/os/getcount.o(.bss);
        build/asm/libultra/io/contpfs.o(.bss);
        build/asm/libultra/io/pidma.o(.bss);
        build/asm/libultra/io/pfssearchfile.o(.bss);
        build/asm/libultra/audio/synthesizer.o(.bss);
        build/asm/libultra/audio/drvrnew.o(.bss);
        build/asm/libultra/audio/mainbus.o(.bss);
        build/asm/libultra/audio/reverb.o(.bss);
        build/asm/libultra/audio/auxbus.o(.bss);
        build/asm/libultra/audio/env.o(.bss);
        build/asm/libultra/audio/resample.o(.bss);
        build/asm/libultra/audio/load.o(.bss);
        build/asm/libultra/os/seteventmesg.o(.bss);
        build/asm/libultra/gu/sqrtf.o(.bss);
        build/asm/libultra/os/afterprenmi.o(.bss);
        build/asm/libultra/io/contquery.o(.bss);
        build/asm/libultra/gu/random.o(.bss);
        build/asm/libultra/os/unmaptlb.o(.bss);
        build/asm/libultra/libc/xprintf.o(.bss);
        build/asm/libultra/audio/filter.o(.bss);
        build/asm/libultra/gu/ortho.o(.bss);
        build/asm/libultra/os/unmaptlball.o(.bss);
        build/asm/libultra/io/epidma.o(.bss);
        build/asm/libultra/audio/heapinit.o(.bss);
        build/asm/libultra/libc/string.o(.bss);
        build/asm/libultra/os/invalicache.o(.bss);
        build/asm/libultra/os/createmesgqueue.o(.bss);
        build/asm/libultra/os/invaldcache.o(.bss);
        build/asm/libultra/audio/synsetfxmix.o(.bss);
        build/asm/libultra/audio/save.o(.bss);
        build/asm/libultra/io/pfsrepairid.o(.bss);
        build/asm/libultra/audio/syngetfxref.o(.bss);
        build/asm/libultra/io/sp.o(.bss);
        build/asm/libultra/io/si.o(.bss);
        build/asm/libultra/gu/translate.o(.bss);
        build/asm/libultra/os/jammesg.o(.bss);
        build/asm/libultra/os/setthreadpri.o(.bss);
        build/asm/libultra/os/getthreadpri.o(.bss);
        build/asm/libultra/io/epirawread.o(.bss);
        build/asm/libultra/io/viswapbuf.o(.bss);
        build/asm/libultra/gu/lookat.o(.bss);
        build/asm/libultra/gu/position.o(.bss);
        build/asm/libultra/io/epirawdma.o(.bss);
        build/asm/libultra/io/sptaskyielded.o(.bss);
        build/asm/libultra/libc/bcmp.o(.bss);
        build/asm/libultra/os/gettime.o(.bss);
        build/asm/libultra/os/timerintr.o(.bss);
        build/asm/libultra/os/setglobalintmask.o(.bss);
        build/asm/libultra/io/aisetfreq.o(.bss);
        build/asm/libultra/gu/normalize.o(.bss);
        build/asm/libultra/os/setcompare.o(.bss);
        build/asm/libultra/libc/bcopy.o(.bss);
        build/asm/libultra/audio/copy.o(.bss);
        build/asm/libultra/os/resetglobalintmask.o(.bss);
        build/asm/libultra/io/pfsdeletefile.o(.bss);
        build/asm/libultra/os/interrupt.o(.bss);
        build/asm/libultra/io/vi.o(.bss);
        build/asm/libultra/io/viswapcontext.o(.bss);
        build/asm/libultra/io/pigetcmdq.o(.bss);
        build/asm/libultra/gu/cosf.o(.bss);
        build/asm/libultra/gu/coss.o(.bss);
        build/asm/libultra/io/visetspecial.o(.bss);
        build/asm/libultra/io/visetevent.o(.bss);
        build/asm/libultra/audio/synaddplayer.o(.bss);
        build/asm/libultra/io/pfsnumfiles.o(.bss);
        build/asm/libultra/io/cartrominit.o(.bss);
        build/asm/libultra/io/pfsselectbank.o(.bss);
        build/asm/libultra/os/setfpccsr.o(.bss);
        build/asm/libultra/io/pfsfilestate.o(.bss);
        build/asm/libultra/io/pfsinitpak.o(.bss);
        build/asm/libultra/io/pfschecker.o(.bss);
        build/asm/libultra/io/aigetlen.o(.bss);
        build/asm/libultra/io/piwrite.o(.bss);
        build/asm/libultra/os/maptlbrdb.o(.bss);
        build/asm/libultra/os/yieldthread.o(.bss);
        build/asm/libultra/audio/synstartvoiceparam.o(.bss);
        build/asm/libultra/os/getcause.o(.bss);
        build/asm/libultra/io/contramwrite.o(.bss);
        build/asm/libultra/io/contramread.o(.bss);
        build/asm/libultra/io/crc.o(.bss);
        build/asm/libultra/io/epirawwrite.o(.bss);
        build/asm/libultra/os/settimer.o(.bss);
        build/asm/libultra/libc/xldtob.o(.bss);
        build/asm/libultra/libc/ldiv.o(.bss);
        build/asm/libultra/libc/xlitob.o(.bss);
        build/asm/libultra/io/sirawwrite.o(.bss);
        build/asm/libultra/io/pirawwrite.o(.bss);
        build/asm/libultra/io/spsetstat.o(.bss);
        build/asm/libultra/io/spgetstat.o(.bss);
        build/asm/libultra/io/vimgr.o(.bss);
        build/asm/libultra/io/vigetcurrcontext.o(.bss);
        build/asm/libultra/os/writebackdcacheall.o(.bss);
        build/asm/libultra/audio/heapalloc.o(.bss);
        build/asm/libultra/os/getcurrfaultthread.o(.bss);
        build/asm/libultra/gu/rotaterpy.o(.bss);
        build/asm/libultra/libc/llcvt.o(.bss);
        build/asm/libultra/os/startthread.o(.bss);
        build/asm/libultra/io/visetyscale.o(.bss);
        build/asm/libultra/audio/synallocfx.o(.bss);
        build/asm/libultra/audio/synstopvoice.o(.bss);
        build/asm/libultra/audio/syndelete.o(.bss);
        build/asm/libultra/io/aisetnextbuf.o(.bss);
        build/asm/libultra/io/ai.o(.bss);
        build/asm/libultra/io/vigetcurrframebuf.o(.bss);
        build/asm/libultra/io/spsetpc.o(.bss);
        . = ALIGN(., 16);
        main_BSS_END = .;
        main_BSS_SIZE = ABSOLUTE(main_BSS_END - main_BSS_START);
    }
    __romPos += SIZEOF(.main);
    __romPos = ALIGN(__romPos, 16);
    . = ALIGN(., 16);
    main_ROM_END = __romPos;
    main_VRAM_END = .;

    common_ROM_START = __romPos;
    common_VRAM = ADDR(.common);
    .common 0x80128900 : AT(common_ROM_START) SUBALIGN(16)
    {
        FILL(0x00000000);
        common_TEXT_START = .;
        build/asm/common/interactables.o(.text);
        build/asm/common/interactables_helpers.o(.text);
        build/asm/common/cutscene_manager.o(.text);
        build/asm/common/cutscene_trigger.o(.text);
        build/asm/common/cutscene.o(.text);
        build/asm/common/stage_select.o(.text);
        build/asm/common/textbox_object.o(.text);
        build/asm/common/textbox.o(.text);
        build/asm/common/lens.o(.text);
        build/asm/common/gameplay_menu_manager.o(.text);
        build/asm/common/hud.o(.text);
        build/asm/common/hud_params.o(.text);
        build/asm/common/renon_shop.o(.text);
        build/asm/C1600.o(.text);
        build/asm/common/menu_alloc_struct.o(.text);
        build/asm/common/gameplay_common_textbox.o(.text);
        build/asm/common/item.o(.text);
        build/asm/common/mini_scroll_setup.o(.text);
        build/asm/C3740.o(.text);
        build/asm/common/distortion.o(.text);
        build/asm/C5D90.o(.text);
        build/asm/C62D0.o(.text);
        build/asm/C77B0.o(.text);
        build/asm/common/options_controller.o(.text);
        build/asm/common/file_select.o(.text);
        build/asm/common/scroll.o(.text);
        build/asm/common/necronomicon.o(.text);
        build/asm/common/necro_work.o(.text);
        build/asm/common/page.o(.text);
        build/asm/common/page_work.o(.text);
        build/asm/common/mark.o(.text);
        build/asm/common/mark_work.o(.text);
        build/asm/common/glance.o(.text);
        build/asm/D7CD0.o(.text);
        build/asm/common/map_manager.o(.text);
        build/asm/DA250.o(.text);
        build/asm/common/map.o(.text);
        build/asm/common/loading_zone.o(.text);
        build/asm/common/squash_point.o(.text);
        build/asm/DDE40.o(.text);
        build/asm/DFBC0.o(.text);
        build/asm/E0A90.o(.text);
        build/asm/E0F00.o(.text);
        build/asm/common/skybox_common_actors.o(.text);
        build/asm/E2DA0.o(.text);
        build/asm/common/room.o(.text);
        build/asm/common/door.o(.text);
        build/asm/common/lever.o(.text);
        build/asm/common/river_water.o(.text);
        build/asm/E72C0.o(.text);
        build/asm/common/object_017C.o(.text);
        build/asm/E7970.o(.text);
        build/asm/common/elevator.o(.text);
        build/asm/E8FA0.o(.text);
        build/asm/common/candle.o(.text);
        build/asm/common/sound_range.o(.text);
        build/asm/ECE20.o(.text);
        build/asm/common/actor_creator.o(.text);
        build/asm/EED20.o(.text);
        . = ALIGN(., 16);
        common_TEXT_END = .;
        common_TEXT_SIZE = ABSOLUTE(common_TEXT_END - common_TEXT_START);
        common_DATA_START = .;
        build/asm/data/common/interactables_tables.data.o(.data);
        build/asm/data/common/interactables.data.o(.data);
        build/asm/data/common/cutscene_manager.data.o(.data);
        build/asm/data/common/cutscene_trigger.data.o(.data);
        build/asm/data/F1DD0.data.o(.data);
        build/asm/data/F30A0.data.o(.data);
        build/asm/data/common/stage_select.data.o(.data);
        build/asm/data/func_80170048.data.o(.data);
        build/asm/data/func_80170124.data.o(.data);
        build/asm/data/F3290.data.o(.data);
        build/asm/data/F38B0.data.o(.data);
        build/asm/data/common/gameplay_menu_manager.data.o(.data);
        build/asm/data/common/hud.data.o(.data);
        build/asm/data/common/renon_shop.data.o(.data);
        build/asm/data/common/gameplay_common_textbox.data.o(.data);
        build/asm/common/item.o(.data);
        build/asm/common/mini_scroll_setup.o(.data);
        build/asm/C3740.o(.data);
        build/asm/data/common/distortion.data.o(.data);
        build/asm/C5D90.o(.data);
        build/asm/C62D0.o(.data);
        build/asm/C77B0.o(.data);
        build/asm/common/options_controller.o(.data);
        build/asm/common/file_select.o(.data);
        build/asm/common/scroll.o(.data);
        build/asm/data/107710.data.o(.data);
        build/asm/data/1077B0.data.o(.data);
        build/asm/data/1078C0.data.o(.data);
        build/asm/data/107B70.data.o(.data);
        build/asm/data/107C80.data.o(.data);
        build/asm/data/common/necronomicon.data.o(.data);
        build/asm/data/common/page.data.o(.data);
        build/asm/data/107FC0.data.o(.data);
        build/asm/data/107FE0.data.o(.data);
        build/asm/data/1080F0.data.o(.data);
        build/asm/data/108160.data.o(.data);
        build/asm/data/108180.data.o(.data);
        build/asm/data/10BAF0.data.o(.data);
        build/asm/data/10CF20.data.o(.data);
        build/asm/data/common/skybox_common_actors.data.o(.data);
        build/asm/data/10DC80.data.o(.data);
        build/asm/data/10DD50.data.o(.data);
        build/asm/data/10DE20.data.o(.data);
        build/asm/data/common/object_017C.data.o(.data);
        build/asm/E7970.o(.data);
        build/asm/common/elevator.o(.data);
        build/asm/E8FA0.o(.data);
        build/asm/common/candle.o(.data);
        build/asm/common/sound_range.o(.data);
        build/asm/ECE20.o(.data);
        build/asm/common/actor_creator.o(.data);
        build/asm/EED20.o(.data);
        build/asm/data/10F180.data.o(.data);
        build/asm/data/110F00.data.o(.data);
        build/asm/data/110F20.data.o(.data);
        build/asm/data/111280.data.o(.data);
        build/asm/data/common/interactables.data.o(.data);
        build/asm/data/common/interactables_helpers.data.o(.data);
        build/asm/data/common/cutscene_trigger.data.o(.data);
        build/asm/common/cutscene.o(.data);
        build/asm/data/common/stage_select.data.o(.data);
        build/asm/common/textbox_object.o(.data);
        build/asm/common/textbox.o(.data);
        build/asm/data/111710.data.o(.data);
        build/asm/data/111800.data.o(.data);
        build/asm/data/common/lens.data.o(.data);
        build/asm/data/common/gameplay_menu_manager.data.o(.data);
        build/asm/data/common/hud.data.o(.data);
        build/asm/common/hud_params.o(.data);
        build/asm/data/common/renon_shop.data.o(.data);
        build/asm/C1600.o(.data);
        build/asm/common/menu_alloc_struct.o(.data);
        build/asm/data/111EC0.data.o(.data);
        build/asm/data/111F10.data.o(.data);
        build/asm/data/common/necronomicon.data.o(.data);
        build/asm/data/common/necro_work.data.o(.data);
        build/asm/data/common/page_work.data.o(.data);
        build/asm/common/mark.o(.data);
        build/asm/common/mark_work.o(.data);
        build/asm/common/glance.o(.data);
        build/asm/D7CD0.o(.data);
        build/asm/common/map_manager.o(.data);
        build/asm/DA250.o(.data);
        build/asm/common/map.o(.data);
        build/asm/common/loading_zone.o(.data);
        build/asm/common/squash_point.o(.data);
        build/asm/DDE40.o(.data);
        build/asm/DFBC0.o(.data);
        build/asm/E0A90.o(.data);
        build/asm/E0F00.o(.data);
        build/asm/data/112610.data.o(.data);
        build/asm/data/112630.data.o(.data);
        build/asm/data/112640.data.o(.data);
        build/asm/data/1126B0.data.o(.data);
        build/asm/data/1127B0.data.o(.data);
        build/asm/data/1128B0.data.o(.data);
        build/asm/data/112DF0.data.o(.data);
        build/asm/data/112E30.data.o(.data);
        build/asm/data/common/skybox_common_actors.data.o(.data);
        build/asm/E2DA0.o(.data);
        build/asm/common/room.o(.data);
        build/asm/common/door.o(.data);
        build/asm/common/lever.o(.data);
        build/asm/common/river_water.o(.data);
        build/asm/E72C0.o(.data);
        build/asm/data/112E70.data.o(.data);
        build/asm/data/112F40.data.o(.data);
        build/asm/data/112FF0.data.o(.data);
        build/asm/data/113010.data.o(.data);
        build/asm/data/113040.data.o(.data);
        build/asm/data/113080.data.o(.data);
        build/asm/data/113180.data.o(.data);
        . = ALIGN(., 16);
        common_DATA_END = .;
        common_DATA_SIZE = ABSOLUTE(common_DATA_END - common_DATA_START);
        common_RODATA_START = .;
        build/asm/common/interactables.o(.rodata);
        build/asm/common/interactables_helpers.o(.rodata);
        build/asm/common/cutscene_manager.o(.rodata);
        build/asm/common/cutscene_trigger.o(.rodata);
        build/asm/common/cutscene.o(.rodata);
        build/asm/common/stage_select.o(.rodata);
        build/asm/common/textbox_object.o(.rodata);
        build/asm/common/textbox.o(.rodata);
        build/asm/common/lens.o(.rodata);
        build/asm/common/gameplay_menu_manager.o(.rodata);
        build/asm/common/hud.o(.rodata);
        build/asm/common/hud_params.o(.rodata);
        build/asm/common/renon_shop.o(.rodata);
        build/asm/C1600.o(.rodata);
        build/asm/common/menu_alloc_struct.o(.rodata);
        build/asm/common/gameplay_common_textbox.o(.rodata);
        build/asm/common/item.o(.rodata);
        build/asm/common/mini_scroll_setup.o(.rodata);
        build/asm/C3740.o(.rodata);
        build/asm/common/distortion.o(.rodata);
        build/asm/C5D90.o(.rodata);
        build/asm/C62D0.o(.rodata);
        build/asm/C77B0.o(.rodata);
        build/asm/common/options_controller.o(.rodata);
        build/asm/common/file_select.o(.rodata);
        build/asm/common/scroll.o(.rodata);
        build/asm/common/necronomicon.o(.rodata);
        build/asm/common/necro_work.o(.rodata);
        build/asm/common/page.o(.rodata);
        build/asm/common/page_work.o(.rodata);
        build/asm/common/mark.o(.rodata);
        build/asm/common/mark_work.o(.rodata);
        build/asm/common/glance.o(.rodata);
        build/asm/D7CD0.o(.rodata);
        build/asm/common/map_manager.o(.rodata);
        build/asm/DA250.o(.rodata);
        build/asm/common/map.o(.rodata);
        build/asm/common/loading_zone.o(.rodata);
        build/asm/common/squash_point.o(.rodata);
        build/asm/DDE40.o(.rodata);
        build/asm/DFBC0.o(.rodata);
        build/asm/E0A90.o(.rodata);
        build/asm/E0F00.o(.rodata);
        build/asm/common/skybox_common_actors.o(.rodata);
        build/asm/E2DA0.o(.rodata);
        build/asm/common/room.o(.rodata);
        build/asm/common/door.o(.rodata);
        build/asm/common/lever.o(.rodata);
        build/asm/common/river_water.o(.rodata);
        build/asm/E72C0.o(.rodata);
        build/asm/common/object_017C.o(.rodata);
        build/asm/E7970.o(.rodata);
        build/asm/common/elevator.o(.rodata);
        build/asm/E8FA0.o(.rodata);
        build/asm/common/candle.o(.rodata);
        build/asm/common/sound_range.o(.rodata);
        build/asm/ECE20.o(.rodata);
        build/asm/common/actor_creator.o(.rodata);
        build/asm/EED20.o(.rodata);
        . = ALIGN(., 16);
        common_RODATA_END = .;
        common_RODATA_SIZE = ABSOLUTE(common_RODATA_END - common_RODATA_START);
    }
    common_bss_VRAM = ADDR(.common_bss);
    .common_bss (NOLOAD) : SUBALIGN(16)
    {
        FILL(0x00000000);
        common_BSS_START = .;
        build/asm/common/interactables.o(.bss);
        build/asm/common/interactables_helpers.o(.bss);
        build/asm/common/cutscene_manager.o(.bss);
        build/asm/common/cutscene_trigger.o(.bss);
        build/asm/common/cutscene.o(.bss);
        build/asm/common/stage_select.o(.bss);
        build/asm/common/textbox_object.o(.bss);
        build/asm/common/textbox.o(.bss);
        build/asm/common/lens.o(.bss);
        build/asm/common/gameplay_menu_manager.o(.bss);
        build/asm/common/hud.o(.bss);
        build/asm/common/hud_params.o(.bss);
        build/asm/common/renon_shop.o(.bss);
        build/asm/C1600.o(.bss);
        build/asm/common/menu_alloc_struct.o(.bss);
        build/asm/common/gameplay_common_textbox.o(.bss);
        build/asm/common/item.o(.bss);
        build/asm/common/mini_scroll_setup.o(.bss);
        build/asm/C3740.o(.bss);
        build/asm/common/distortion.o(.bss);
        build/asm/C5D90.o(.bss);
        build/asm/C62D0.o(.bss);
        build/asm/C77B0.o(.bss);
        build/asm/common/options_controller.o(.bss);
        build/asm/common/file_select.o(.bss);
        build/asm/common/scroll.o(.bss);
        build/asm/common/necronomicon.o(.bss);
        build/asm/common/necro_work.o(.bss);
        build/asm/common/page.o(.bss);
        build/asm/common/page_work.o(.bss);
        build/asm/common/mark.o(.bss);
        build/asm/common/mark_work.o(.bss);
        build/asm/common/glance.o(.bss);
        build/asm/D7CD0.o(.bss);
        build/asm/common/map_manager.o(.bss);
        build/asm/DA250.o(.bss);
        build/asm/common/map.o(.bss);
        build/asm/common/loading_zone.o(.bss);
        build/asm/common/squash_point.o(.bss);
        build/asm/DDE40.o(.bss);
        build/asm/DFBC0.o(.bss);
        build/asm/E0A90.o(.bss);
        build/asm/E0F00.o(.bss);
        build/asm/common/skybox_common_actors.o(.bss);
        build/asm/E2DA0.o(.bss);
        build/asm/common/room.o(.bss);
        build/asm/common/door.o(.bss);
        build/asm/common/lever.o(.bss);
        build/asm/common/river_water.o(.bss);
        build/asm/E72C0.o(.bss);
        build/asm/common/object_017C.o(.bss);
        build/asm/E7970.o(.bss);
        build/asm/common/elevator.o(.bss);
        build/asm/E8FA0.o(.bss);
        build/asm/common/candle.o(.bss);
        build/asm/common/sound_range.o(.bss);
        build/asm/ECE20.o(.bss);
        build/asm/common/actor_creator.o(.bss);
        build/asm/EED20.o(.bss);
        . = ALIGN(., 16);
        common_BSS_END = .;
        common_BSS_SIZE = ABSOLUTE(common_BSS_END - common_BSS_START);
    }
    __romPos += SIZEOF(.common);
    __romPos = ALIGN(__romPos, 16);
    . = ALIGN(., 16);
    common_ROM_END = __romPos;
    common_VRAM_END = .;

    /DISCARD/ :
    {
        *(*);
    }
}
